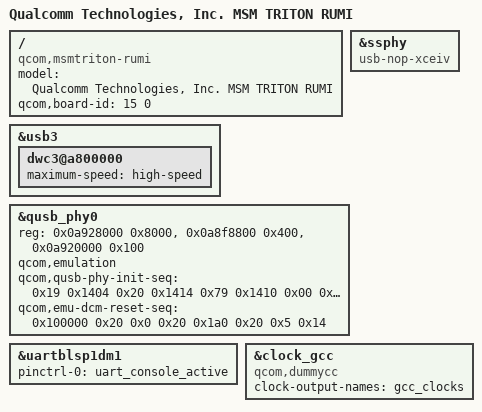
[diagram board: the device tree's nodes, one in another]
/* Copyright (c) 2016, The Linux Foundation. All rights reserved.
 *
 * This program is free software; you can redistribute it and/or modify
 * it under the terms of the GNU General Public License version 2 and
 * only version 2 as published by the Free Software Foundation.
 *
 * This program is distributed in the hope that it will be useful,
 * but WITHOUT ANY WARRANTY; without even the implied warranty of
 * MERCHANTABILITY or FITNESS FOR A PARTICULAR PURPOSE.  See the
 * GNU General Public License for more details.
 */


/dts-v1/;

#include "msmtriton.dtsi"
#include "msmfalcon-pinctrl.dtsi"

/ {
	model = "Qualcomm Technologies, Inc. MSM TRITON RUMI";
	compatible = "qcom,msmtriton-rumi", "qcom,msmtriton", "qcom,rumi";
	qcom,board-id = <15 0>;
};

&usb3 {
	dwc3@a800000 {
		maximum-speed = "high-speed";
	};
};

&ssphy {
	compatible =  "usb-nop-xceiv";
};

&qusb_phy0 {
	reg = <0x0a928000 0x8000>,
		<0x0a8f8800 0x400>,
		<0x0a920000 0x100>;
	reg-names = "qusb_phy_base",
		"qscratch_base",
		"emu_phy_base";
	qcom,emulation;
	qcom,qusb-phy-init-seq = <0x19 0x1404
				0x20 0x1414
				0x79 0x1410
				0x00 0x1418
				0x99 0x1404
				0x04 0x1408
				0xd9 0x1404>;
	qcom,emu-dcm-reset-seq = <0x100000 0x20
				0x0 0x20
				0x1a0 0x20
				0x5 0x14>;
};

&uartblsp1dm1 {
	status = "ok";
	pinctrl-names = "default";
	pinctrl-0 = <&uart_console_active>;
};

&clock_gcc {
	compatible = "qcom,dummycc";
	clock-output-names = "gcc_clocks";
};
